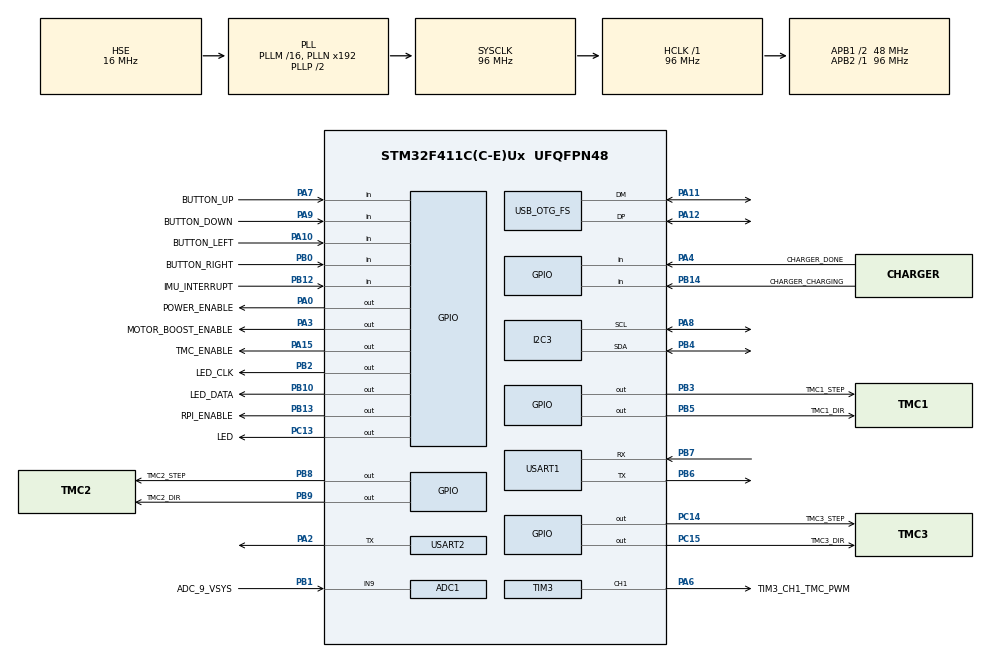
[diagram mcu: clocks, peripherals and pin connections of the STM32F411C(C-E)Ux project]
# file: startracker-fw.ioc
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ADC1.Channel-0\#ChannelRegularConversion=ADC_CHANNEL_9
ADC1.Channel-1\#ChannelRegularConversion=ADC_CHANNEL_VREFINT
ADC1.ClockPrescaler=ADC_CLOCK_SYNC_PCLK_DIV8
ADC1.ContinuousConvMode=ENABLE
ADC1.DMAContinuousRequests=ENABLE
ADC1.EOCSelection=ADC_EOC_SEQ_CONV
ADC1.NbrOfConversion=2
ADC1.NbrOfConversionFlag=1
ADC1.Rank-0\#ChannelRegularConversion=1
ADC1.Rank-1\#ChannelRegularConversion=2
ADC1.SamplingTime-0\#ChannelRegularConversion=ADC_SAMPLETIME_480CYCLES
ADC1.SamplingTime-1\#ChannelRegularConversion=ADC_SAMPLETIME_480CYCLES
ADC1.master=1
Dma.ADC1.2.Direction=DMA_PERIPH_TO_MEMORY
Dma.ADC1.2.FIFOMode=DMA_FIFOMODE_DISABLE
Dma.ADC1.2.Instance=DMA2_Stream0
Dma.ADC1.2.MemDataAlignment=DMA_MDATAALIGN_WORD
Dma.ADC1.2.MemInc=DMA_MINC_ENABLE
Dma.ADC1.2.Mode=DMA_CIRCULAR
Dma.ADC1.2.PeriphDataAlignment=DMA_PDATAALIGN_WORD
Dma.ADC1.2.PeriphInc=DMA_PINC_DISABLE
Dma.ADC1.2.Priority=DMA_PRIORITY_LOW
Dma.I2C3_RX.0.Direction=DMA_PERIPH_TO_MEMORY
Dma.I2C3_RX.0.FIFOMode=DMA_FIFOMODE_DISABLE
Dma.I2C3_RX.0.Instance=DMA1_Stream1
Dma.I2C3_RX.0.MemDataAlignment=DMA_MDATAALIGN_BYTE
Dma.I2C3_RX.0.MemInc=DMA_MINC_ENABLE
Dma.I2C3_RX.0.Mode=DMA_NORMAL
Dma.I2C3_RX.0.PeriphDataAlignment=DMA_PDATAALIGN_BYTE
Dma.I2C3_RX.0.PeriphInc=DMA_PINC_DISABLE
Dma.I2C3_RX.0.Priority=DMA_PRIORITY_MEDIUM
Dma.I2C3_TX.1.Direction=DMA_MEMORY_TO_PERIPH
Dma.I2C3_TX.1.FIFOMode=DMA_FIFOMODE_DISABLE
Dma.I2C3_TX.1.Instance=DMA1_Stream4
Dma.I2C3_TX.1.MemDataAlignment=DMA_MDATAALIGN_BYTE
Dma.I2C3_TX.1.MemInc=DMA_MINC_ENABLE
Dma.I2C3_TX.1.Mode=DMA_NORMAL
Dma.I2C3_TX.1.PeriphDataAlignment=DMA_PDATAALIGN_BYTE
Dma.I2C3_TX.1.PeriphInc=DMA_PINC_DISABLE
Dma.I2C3_TX.1.Priority=DMA_PRIORITY_MEDIUM
Dma.Request0=I2C3_RX
Dma.Request1=I2C3_TX
Dma.Request2=ADC1
I2C3.I2C_Mode=I2C_Fast
Mcu.Family=STM32F4
Mcu.Name=STM32F411C(C-E)Ux
Mcu.Package=UFQFPN48
NVIC.DMA1_Stream1_IRQn=true\:0\:0\:false\:false\:true\:false\:true\:true
NVIC.DMA1_Stream4_IRQn=true\:0\:0\:false\:false\:true\:false\:true\:true
NVIC.DMA2_Stream0_IRQn=true\:0\:0\:false\:false\:true\:false\:true\:true
NVIC.I2C3_ER_IRQn=true\:0\:0\:false\:false\:true\:true\:true\:true
NVIC.I2C3_EV_IRQn=true\:0\:0\:false\:false\:true\:true\:true\:true
NVIC.OTG_FS_IRQn=true\:0\:0\:false\:false\:true\:false\:true\:true
NVIC.PriorityGroup=NVIC_PRIORITYGROUP_4
NVIC.TIM4_IRQn=true\:0\:0\:false\:false\:true\:true\:true\:true
NVIC.USART1_IRQn=true\:0\:0\:false\:false\:true\:true\:true\:true
PA0-WKUP.GPIO_Label=POWER_ENABLE
PA0-WKUP.Signal=GPIO_Output
PA10.GPIO_Label=BUTTON_LEFT
PA10.Signal=GPIO_Input
PA11.Mode=Device_Only
PA11.Signal=USB_OTG_FS_DM
PA12.Mode=Device_Only
PA12.Signal=USB_OTG_FS_DP
PA13.Mode=Serial_Wire
PA13.Signal=SYS_JTMS-SWDIO
PA14.Mode=Serial_Wire
PA14.Signal=SYS_JTCK-SWCLK
PA15.GPIO_Label=TMC_ENABLE
PA15.PinState=GPIO_PIN_SET
PA15.Signal=GPIO_Output
PA2.GPIO_ModeDefaultOD=GPIO_MODE_AF_OD
PA2.GPIO_PuPd=GPIO_PULLUP
PA2.Mode=Half_duplex(single_wire_mode)
PA2.Signal=USART2_TX
PA3.GPIO_Label=MOTOR_BOOST_ENABLE
PA3.Signal=GPIO_Output
PA4.GPIO_Label=CHARGER_DONE
PA4.Signal=GPIO_Input
PA6.GPIO_Label=TIM3_CH1_TMC_PWM
PA6.Signal=S_TIM3_CH1
PA7.GPIO_Label=BUTTON_UP
PA7.Signal=GPIO_Input
PA8.GPIO_Pu=GPIO_PULLUP
PA8.Mode=I2C
PA8.Signal=I2C3_SCL
PA9.GPIO_Label=BUTTON_DOWN
PA9.Signal=GPIO_Input
PB0.GPIO_Label=BUTTON_RIGHT
PB0.Signal=GPIO_Input
PB1.GPIO_Label=ADC_9_VSYS
PB1.Signal=ADCx_IN9
PB10.GPIO_Label=LED_DATA
PB10.Signal=GPIO_Output
PB12.GPIO_Label=IMU_INTERRUPT
PB12.Signal=GPIO_Input
PB13.GPIO_Label=RPI_ENABLE
PB13.Signal=GPIO_Output
PB14.GPIO_Label=CHARGER_CHARGING
PB14.Signal=GPIO_Input
PB2.GPIO_Label=LED_CLK
PB2.Signal=GPIO_Output
PB3.GPIO_Label=TMC1_STEP
PB3.Signal=GPIO_Output
PB4.GPIO_Pu=GPIO_PULLUP
PB4.Mode=I2C
PB4.Signal=I2C3_SDA
PB5.GPIO_Label=TMC1_DIR
PB5.Signal=GPIO_Output
PB6.Mode=Asynchronous
PB6.Signal=USART1_TX
PB7.Mode=Asynchronous
PB7.Signal=USART1_RX
PB8.GPIO_Label=TMC2_STEP
PB8.Signal=GPIO_Output
PB9.GPIO_Label=TMC2_DIR
PB9.Signal=GPIO_Output
PC13-ANTI_TAMP.GPIO_Label=LED
PC13-ANTI_TAMP.Signal=GPIO_Output
PC14-OSC32_IN.GPIO_Label=TMC3_STEP
PC14-OSC32_IN.Signal=GPIO_Output
PC15-OSC32_OUT.GPIO_Label=TMC3_DIR
PC15-OSC32_OUT.Signal=GPIO_Output
PH0\ -\ OSC_IN.Mode=HSE-External-Oscillator
PH0\ -\ OSC_IN.Signal=RCC_OSC_IN
PH1\ -\ OSC_OUT.Mode=HSE-External-Oscillator
PH1\ -\ OSC_OUT.Signal=RCC_OSC_OUT
ProjectManager.HeapSize=0x200
ProjectManager.StackSize=0x400
ProjectManager.TargetToolchain=STM32CubeIDE
RCC.48MHZClocksFreq_Value=48000000
RCC.AHBFreq_Value=96000000
RCC.APB1CLKDivider=RCC_HCLK_DIV2
RCC.APB1Freq_Value=48000000
RCC.APB1TimFreq_Value=96000000
RCC.APB2Freq_Value=96000000
RCC.APB2TimFreq_Value=96000000
RCC.CortexFreq_Value=96000000
RCC.HCLKFreq_Value=96000000
RCC.HSE_VALUE=16000000
RCC.HSI_VALUE=16000000
RCC.LSE_VALUE=32768
RCC.SYSCLKFreq_VALUE=96000000
RCC.SYSCLKSource=RCC_SYSCLKSOURCE_PLLCLK
RCC.VCOOutputFreq_Value=192000000
SH.ADCx_IN9.0=ADC1_IN9,IN9
SH.S_TIM3_CH1.0=TIM3_CH1,PWM Generation1 CH1
TIM3.AutoReloadPreload=TIM_AUTORELOAD_PRELOAD_ENABLE
TIM3.Channel-PWM\ Generation1\ CH1=TIM_CHANNEL_1
TIM3.Period=256
TIM3.Prescaler=0
TIM4.Period=250-1
TIM4.Prescaler=96-1
TIM5.Prescaler=96-1
USART1.VirtualMode=VM_ASYNC
USART2.BaudRate=38400
USART2.Mode=MODE_TX
USART2.VirtualMode=VM_ASYNC
USB_DEVICE.CLASS_NAME_FS=CDC
USB_DEVICE.VirtualMode=Cdc
USB_DEVICE.VirtualModeFS=Cdc_FS
USB_OTG_FS.VirtualMode=Device_Only
VP_ADC1_Vref_Input.Mode=IN-Vrefint
VP_TIM4_VS_ClockSourceINT.Mode=Internal
VP_TIM5_VS_ClockSourceINT.Mode=Internal
VP_USB_DEVICE_VS_USB_DEVICE_CDC_FS.Mode=CDC_FS
board=custom

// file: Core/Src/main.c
/* USER CODE BEGIN Header */
/**
  ******************************************************************************
  * @file           : main.c
  * @brief          : Main program body
  ******************************************************************************
  * @attention
  *
  * Copyright (c) 2023 STMicroelectronics.
  * All rights reserved.
  *
  * This software is licensed under terms that can be found in the LICENSE file
  * in the root directory of this software component.
  * If no LICENSE file comes with this software, it is provided AS-IS.
  *
  ******************************************************************************
  */
/* USER CODE END Header */
#include "main.h"
#include "usb_device.h"

/* USER CODE BEGIN Includes */
#include "application.h"
/* USER CODE END Includes */

ADC_HandleTypeDef hadc1;
DMA_HandleTypeDef hdma_adc1;

I2C_HandleTypeDef hi2c3;
DMA_HandleTypeDef hdma_i2c3_rx;
DMA_HandleTypeDef hdma_i2c3_tx;

TIM_HandleTypeDef htim3;
TIM_HandleTypeDef htim4;
TIM_HandleTypeDef htim5;

UART_HandleTypeDef huart1;
UART_HandleTypeDef huart2;

void SystemClock_Config(void);
static void MX_GPIO_Init(void);
static void MX_DMA_Init(void);
static void MX_I2C3_Init(void);
static void MX_USART1_UART_Init(void);
static void MX_USART2_UART_Init(void);
static void MX_TIM3_Init(void);
static void MX_TIM4_Init(void);
static void MX_TIM5_Init(void);
static void MX_ADC1_Init(void);

int main(void)
{
  __disable_irq();

  /* MCU Configuration--------------------------------------------------------*/

  /* Reset of all peripherals, Initializes the Flash interface and the Systick. */
  HAL_Init();

  /* Configure the system clock */
  SystemClock_Config();

  /* USER CODE BEGIN SysInit */
//  HAL_SYSTICK_Config(10);
  __enable_irq();
  /* USER CODE END SysInit */

  /* Initialize all configured peripherals */
  MX_GPIO_Init();
  MX_DMA_Init();
  MX_I2C3_Init();
  MX_USB_DEVICE_Init();
  MX_USART1_UART_Init();
  MX_USART2_UART_Init();
  MX_TIM3_Init();
  MX_TIM4_Init();
  MX_TIM5_Init();
  MX_ADC1_Init();
  __disable_irq();

  /* Infinite loop */
  /* USER CODE BEGIN WHILE */
  HAL_NVIC_SetPriority(SysTick_IRQn, 14, 0U);
  HAL_NVIC_SetPriority(PendSV_IRQn, 15, 0U);

  app_init();
  while (1)
  {
    /* USER CODE END WHILE */

  }
}

void SystemClock_Config(void)
{
  RCC_OscInitTypeDef RCC_OscInitStruct = {0};
  RCC_ClkInitTypeDef RCC_ClkInitStruct = {0};

  /** Configure the main internal regulator output voltage
  */
  __HAL_RCC_PWR_CLK_ENABLE();
  __HAL_PWR_VOLTAGESCALING_CONFIG(PWR_REGULATOR_VOLTAGE_SCALE1);

  /** Initializes the RCC Oscillators according to the specified parameters
  * in the RCC_OscInitTypeDef structure.
  */
  RCC_OscInitStruct.OscillatorType = RCC_OSCILLATORTYPE_HSE;
  RCC_OscInitStruct.HSEState = RCC_HSE_ON;
  RCC_OscInitStruct.PLL.PLLState = RCC_PLL_ON;
  RCC_OscInitStruct.PLL.PLLSource = RCC_PLLSOURCE_HSE;
  RCC_OscInitStruct.PLL.PLLM = 16;
  RCC_OscInitStruct.PLL.PLLN = 192;
  RCC_OscInitStruct.PLL.PLLP = RCC_PLLP_DIV2;
  RCC_OscInitStruct.PLL.PLLQ = 4;
  if (HAL_RCC_OscConfig(&RCC_OscInitStruct) != HAL_OK)
  {
    Error_Handler();
  }

  /** Initializes the CPU, AHB and APB buses clocks
  */
  RCC_ClkInitStruct.ClockType = RCC_CLOCKTYPE_HCLK|RCC_CLOCKTYPE_SYSCLK
                              |RCC_CLOCKTYPE_PCLK1|RCC_CLOCKTYPE_PCLK2;
  RCC_ClkInitStruct.SYSCLKSource = RCC_SYSCLKSOURCE_PLLCLK;
  RCC_ClkInitStruct.AHBCLKDivider = RCC_SYSCLK_DIV1;
  RCC_ClkInitStruct.APB1CLKDivider = RCC_HCLK_DIV2;
  RCC_ClkInitStruct.APB2CLKDivider = RCC_HCLK_DIV1;

  if (HAL_RCC_ClockConfig(&RCC_ClkInitStruct, FLASH_LATENCY_3) != HAL_OK)
  {
    Error_Handler();
  }
}

static void MX_ADC1_Init(void)
{

  ADC_ChannelConfTypeDef sConfig = {0};

  /** Configure the global features of the ADC (Clock, Resolution, Data Alignment and number of conversion)
  */
  hadc1.Instance = ADC1;
  hadc1.Init.ClockPrescaler = ADC_CLOCK_SYNC_PCLK_DIV8;
  hadc1.Init.Resolution = ADC_RESOLUTION_12B;
  hadc1.Init.ScanConvMode = ENABLE;
  hadc1.Init.ContinuousConvMode = ENABLE;
  hadc1.Init.DiscontinuousConvMode = DISABLE;
  hadc1.Init.ExternalTrigConvEdge = ADC_EXTERNALTRIGCONVEDGE_NONE;
  hadc1.Init.ExternalTrigConv = ADC_SOFTWARE_START;
  hadc1.Init.DataAlign = ADC_DATAALIGN_RIGHT;
  hadc1.Init.NbrOfConversion = 2;
  hadc1.Init.DMAContinuousRequests = ENABLE;
  hadc1.Init.EOCSelection = ADC_EOC_SEQ_CONV;
  if (HAL_ADC_Init(&hadc1) != HAL_OK)
  {
    Error_Handler();
  }

  /** Configure for the selected ADC regular channel its corresponding rank in the sequencer and its sample time.
  */
  sConfig.Channel = ADC_CHANNEL_9;
  sConfig.Rank = 1;
  sConfig.SamplingTime = ADC_SAMPLETIME_480CYCLES;
  if (HAL_ADC_ConfigChannel(&hadc1, &sConfig) != HAL_OK)
  {
    Error_Handler();
  }

  /** Configure for the selected ADC regular channel its corresponding rank in the sequencer and its sample time.
  */
  sConfig.Channel = ADC_CHANNEL_VREFINT;
  sConfig.Rank = 2;
  if (HAL_ADC_ConfigChannel(&hadc1, &sConfig) != HAL_OK)
  {
    Error_Handler();
  }

}

static void MX_I2C3_Init(void)
{

  hi2c3.Instance = I2C3;
  hi2c3.Init.ClockSpeed = 400000;
  hi2c3.Init.DutyCycle = I2C_DUTYCYCLE_2;
  hi2c3.Init.OwnAddress1 = 0;
  hi2c3.Init.AddressingMode = I2C_ADDRESSINGMODE_7BIT;
  hi2c3.Init.DualAddressMode = I2C_DUALADDRESS_DISABLE;
  hi2c3.Init.OwnAddress2 = 0;
  hi2c3.Init.GeneralCallMode = I2C_GENERALCALL_DISABLE;
  hi2c3.Init.NoStretchMode = I2C_NOSTRETCH_DISABLE;
  if (HAL_I2C_Init(&hi2c3) != HAL_OK)
  {
    Error_Handler();
  }

}

static void MX_TIM3_Init(void)
{

  TIM_MasterConfigTypeDef sMasterConfig = {0};
  TIM_OC_InitTypeDef sConfigOC = {0};

  htim3.Instance = TIM3;
  htim3.Init.Prescaler = 0;
  htim3.Init.CounterMode = TIM_COUNTERMODE_UP;
  htim3.Init.Period = 256;
  htim3.Init.ClockDivision = TIM_CLOCKDIVISION_DIV1;
  htim3.Init.AutoReloadPreload = TIM_AUTORELOAD_PRELOAD_ENABLE;
  if (HAL_TIM_PWM_Init(&htim3) != HAL_OK)
  {
    Error_Handler();
  }
  sMasterConfig.MasterOutputTrigger = TIM_TRGO_RESET;
  sMasterConfig.MasterSlaveMode = TIM_MASTERSLAVEMODE_DISABLE;
  if (HAL_TIMEx_MasterConfigSynchronization(&htim3, &sMasterConfig) != HAL_OK)
  {
    Error_Handler();
  }
  sConfigOC.OCMode = TIM_OCMODE_PWM1;
  sConfigOC.Pulse = 0;
  sConfigOC.OCPolarity = TIM_OCPOLARITY_HIGH;
  sConfigOC.OCFastMode = TIM_OCFAST_DISABLE;
  if (HAL_TIM_PWM_ConfigChannel(&htim3, &sConfigOC, TIM_CHANNEL_1) != HAL_OK)
  {
    Error_Handler();
  }
  HAL_TIM_MspPostInit(&htim3);

}

static void MX_TIM4_Init(void)
{

  TIM_ClockConfigTypeDef sClockSourceConfig = {0};
  TIM_MasterConfigTypeDef sMasterConfig = {0};

  htim4.Instance = TIM4;
  htim4.Init.Prescaler = 96-1;
  htim4.Init.CounterMode = TIM_COUNTERMODE_UP;
  htim4.Init.Period = 250-1;
  htim4.Init.ClockDivision = TIM_CLOCKDIVISION_DIV1;
  htim4.Init.AutoReloadPreload = TIM_AUTORELOAD_PRELOAD_DISABLE;
  if (HAL_TIM_Base_Init(&htim4) != HAL_OK)
  {
    Error_Handler();
  }
  sClockSourceConfig.ClockSource = TIM_CLOCKSOURCE_INTERNAL;
  if (HAL_TIM_ConfigClockSource(&htim4, &sClockSourceConfig) != HAL_OK)
  {
    Error_Handler();
  }
  sMasterConfig.MasterOutputTrigger = TIM_TRGO_RESET;
  sMasterConfig.MasterSlaveMode = TIM_MASTERSLAVEMODE_DISABLE;
  if (HAL_TIMEx_MasterConfigSynchronization(&htim4, &sMasterConfig) != HAL_OK)
  {
    Error_Handler();
  }

}

static void MX_TIM5_Init(void)
{

  TIM_ClockConfigTypeDef sClockSourceConfig = {0};
  TIM_MasterConfigTypeDef sMasterConfig = {0};

  htim5.Instance = TIM5;
  htim5.Init.Prescaler = 96-1;
  htim5.Init.CounterMode = TIM_COUNTERMODE_UP;
  htim5.Init.Period = 4294967295;
  htim5.Init.ClockDivision = TIM_CLOCKDIVISION_DIV1;
  htim5.Init.AutoReloadPreload = TIM_AUTORELOAD_PRELOAD_DISABLE;
  if (HAL_TIM_Base_Init(&htim5) != HAL_OK)
  {
    Error_Handler();
  }
  sClockSourceConfig.ClockSource = TIM_CLOCKSOURCE_INTERNAL;
  if (HAL_TIM_ConfigClockSource(&htim5, &sClockSourceConfig) != HAL_OK)
  {
    Error_Handler();
  }
  sMasterConfig.MasterOutputTrigger = TIM_TRGO_RESET;
  sMasterConfig.MasterSlaveMode = TIM_MASTERSLAVEMODE_DISABLE;
  if (HAL_TIMEx_MasterConfigSynchronization(&htim5, &sMasterConfig) != HAL_OK)
  {
    Error_Handler();
  }

}

static void MX_USART1_UART_Init(void)
{

  huart1.Instance = USART1;
  huart1.Init.BaudRate = 115200;
  huart1.Init.WordLength = UART_WORDLENGTH_8B;
  huart1.Init.StopBits = UART_STOPBITS_1;
  huart1.Init.Parity = UART_PARITY_NONE;
  huart1.Init.Mode = UART_MODE_TX_RX;
  huart1.Init.HwFlowCtl = UART_HWCONTROL_NONE;
  huart1.Init.OverSampling = UART_OVERSAMPLING_16;
  if (HAL_UART_Init(&huart1) != HAL_OK)
  {
    Error_Handler();
  }

}

static void MX_USART2_UART_Init(void)
{

  huart2.Instance = USART2;
  huart2.Init.BaudRate = 38400;
  huart2.Init.WordLength = UART_WORDLENGTH_8B;
  huart2.Init.StopBits = UART_STOPBITS_1;
  huart2.Init.Parity = UART_PARITY_NONE;
  huart2.Init.Mode = UART_MODE_TX;
  huart2.Init.HwFlowCtl = UART_HWCONTROL_NONE;
  huart2.Init.OverSampling = UART_OVERSAMPLING_16;
  if (HAL_HalfDuplex_Init(&huart2) != HAL_OK)
  {
    Error_Handler();
  }

}

static void MX_DMA_Init(void)
{

  /* DMA controller clock enable */
  __HAL_RCC_DMA1_CLK_ENABLE();
  __HAL_RCC_DMA2_CLK_ENABLE();

  /* DMA interrupt init */
  /* DMA1_Stream1_IRQn interrupt configuration */
  HAL_NVIC_SetPriority(DMA1_Stream1_IRQn, 0, 0);
  HAL_NVIC_EnableIRQ(DMA1_Stream1_IRQn);
  /* DMA1_Stream4_IRQn interrupt configuration */
  HAL_NVIC_SetPriority(DMA1_Stream4_IRQn, 0, 0);
  HAL_NVIC_EnableIRQ(DMA1_Stream4_IRQn);
  /* DMA2_Stream0_IRQn interrupt configuration */
  HAL_NVIC_SetPriority(DMA2_Stream0_IRQn, 0, 0);
  HAL_NVIC_EnableIRQ(DMA2_Stream0_IRQn);

}

static void MX_GPIO_Init(void)
{
  GPIO_InitTypeDef GPIO_InitStruct = {0};

  /* GPIO Ports Clock Enable */
  __HAL_RCC_GPIOC_CLK_ENABLE();
  __HAL_RCC_GPIOH_CLK_ENABLE();
  __HAL_RCC_GPIOA_CLK_ENABLE();
  __HAL_RCC_GPIOB_CLK_ENABLE();

  /*Configure GPIO pin Output Level */
  HAL_GPIO_WritePin(GPIOC, LED_Pin|TMC3_STEP_Pin|TMC3_DIR_Pin, GPIO_PIN_RESET);

  /*Configure GPIO pin Output Level */
  HAL_GPIO_WritePin(GPIOA, POWER_ENABLE_Pin|MOTOR_BOOST_ENABLE_Pin, GPIO_PIN_RESET);

  /*Configure GPIO pin Output Level */
  HAL_GPIO_WritePin(GPIOB, LED_CLK_Pin|LED_DATA_Pin|RPI_ENABLE_Pin|TMC1_STEP_Pin
                          |TMC1_DIR_Pin|TMC2_STEP_Pin|TMC2_DIR_Pin, GPIO_PIN_RESET);

  /*Configure GPIO pin Output Level */
  HAL_GPIO_WritePin(TMC_ENABLE_GPIO_Port, TMC_ENABLE_Pin, GPIO_PIN_SET);

  /*Configure GPIO pins : LED_Pin TMC3_STEP_Pin TMC3_DIR_Pin */
  GPIO_InitStruct.Pin = LED_Pin|TMC3_STEP_Pin|TMC3_DIR_Pin;
  GPIO_InitStruct.Mode = GPIO_MODE_OUTPUT_PP;
  GPIO_InitStruct.Pull = GPIO_NOPULL;
  GPIO_InitStruct.Speed = GPIO_SPEED_FREQ_LOW;
  HAL_GPIO_Init(GPIOC, &GPIO_InitStruct);

  /*Configure GPIO pins : POWER_ENABLE_Pin MOTOR_BOOST_ENABLE_Pin TMC_ENABLE_Pin */
  GPIO_InitStruct.Pin = POWER_ENABLE_Pin|MOTOR_BOOST_ENABLE_Pin|TMC_ENABLE_Pin;
  GPIO_InitStruct.Mode = GPIO_MODE_OUTPUT_PP;
  GPIO_InitStruct.Pull = GPIO_NOPULL;
  GPIO_InitStruct.Speed = GPIO_SPEED_FREQ_LOW;
  HAL_GPIO_Init(GPIOA, &GPIO_InitStruct);

  /*Configure GPIO pins : CHARGER_DONE_Pin BUTTON_UP_Pin BUTTON_DOWN_Pin BUTTON_LEFT_Pin */
  GPIO_InitStruct.Pin = CHARGER_DONE_Pin|BUTTON_UP_Pin|BUTTON_DOWN_Pin|BUTTON_LEFT_Pin;
  GPIO_InitStruct.Mode = GPIO_MODE_INPUT;
  GPIO_InitStruct.Pull = GPIO_NOPULL;
  HAL_GPIO_Init(GPIOA, &GPIO_InitStruct);

  /*Configure GPIO pins : BUTTON_RIGHT_Pin IMU_INTERRUPT_Pin CHARGER_CHARGING_Pin */
  GPIO_InitStruct.Pin = BUTTON_RIGHT_Pin|IMU_INTERRUPT_Pin|CHARGER_CHARGING_Pin;
  GPIO_InitStruct.Mode = GPIO_MODE_INPUT;
  GPIO_InitStruct.Pull = GPIO_NOPULL;
  HAL_GPIO_Init(GPIOB, &GPIO_InitStruct);

  /*Configure GPIO pins : LED_CLK_Pin LED_DATA_Pin RPI_ENABLE_Pin TMC1_STEP_Pin
                           TMC1_DIR_Pin TMC2_STEP_Pin TMC2_DIR_Pin */
  GPIO_InitStruct.Pin = LED_CLK_Pin|LED_DATA_Pin|RPI_ENABLE_Pin|TMC1_STEP_Pin
                          |TMC1_DIR_Pin|TMC2_STEP_Pin|TMC2_DIR_Pin;
  GPIO_InitStruct.Mode = GPIO_MODE_OUTPUT_PP;
  GPIO_InitStruct.Pull = GPIO_NOPULL;
  GPIO_InitStruct.Speed = GPIO_SPEED_FREQ_LOW;
  HAL_GPIO_Init(GPIOB, &GPIO_InitStruct);

}

void Error_Handler(void)
{
  __disable_irq();
  while (1)
  {
  }
}
